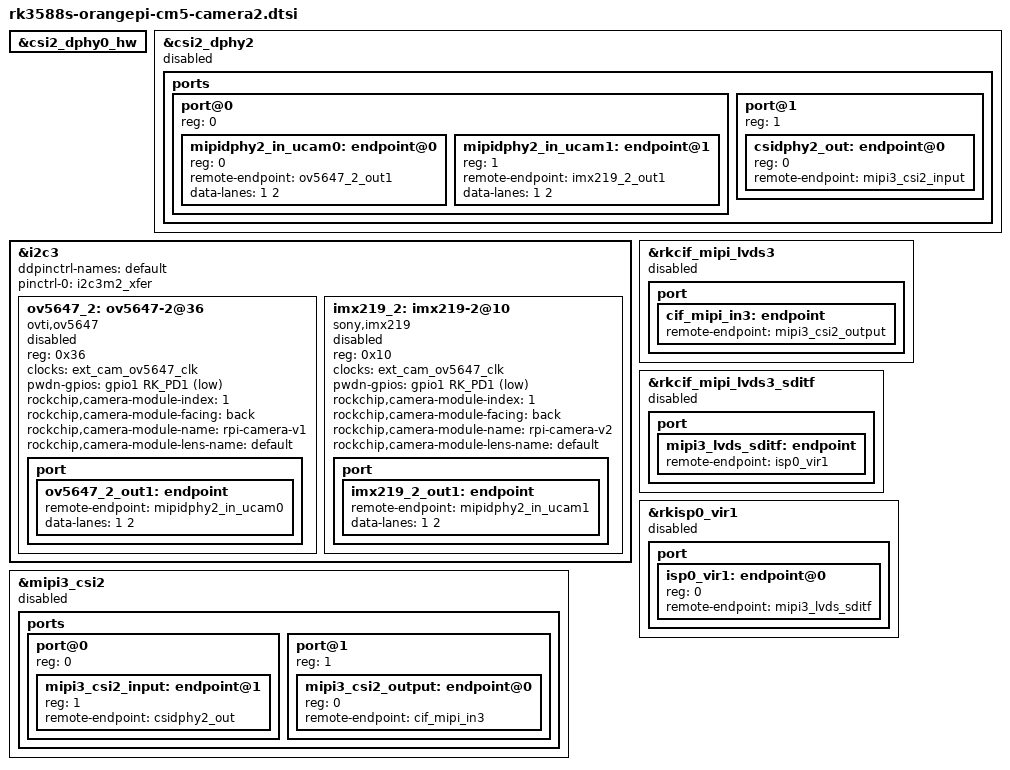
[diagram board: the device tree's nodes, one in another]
// SPDX-License-Identifier: (GPL-2.0+ OR MIT)
/*
 * Copyright (c) 2021 Rockchip Electronics Co., Ltd.
 *
 */

&csi2_dphy0_hw {
	status = "okay";
};

&csi2_dphy2 {
	status = "disabled";
	ports {
		#address-cells = <1>;
		#size-cells = <0>;
		port@0 {
			reg = <0>;
			#address-cells = <1>;
			#size-cells = <0>;

			mipidphy2_in_ucam0: endpoint@0 {
				reg = <0>;
				remote-endpoint = <&ov5647_2_out1>;
				data-lanes = <1 2>;
			};

			mipidphy2_in_ucam1: endpoint@1 {
				reg = <1>;
				remote-endpoint = <&imx219_2_out1>;
				data-lanes = <1 2>;
			};
		};
		port@1 {
		        reg = <1>;
		        #address-cells = <1>;
		        #size-cells = <0>;
		        csidphy2_out: endpoint@0 {
		                reg = <0>;
		                remote-endpoint = <&mipi3_csi2_input>;
		        };
		};
	};
};

&i2c3 {
	status = "okay";
	ddpinctrl-names = "default";
	pinctrl-0 = <&i2c3m2_xfer>;

	ov5647_2: ov5647-2@36 {
		status = "disabled";
		compatible = "ovti,ov5647";
		reg = <0x36>;
		clocks = <&ext_cam_ov5647_clk>;
		clock-names = "ext_cam_ov5647_clk";
		pwdn-gpios = <&gpio1 RK_PD1 GPIO_ACTIVE_LOW>;
		rockchip,camera-module-index = <1>;
		rockchip,camera-module-facing = "back";
		rockchip,camera-module-name = "rpi-camera-v1";
		rockchip,camera-module-lens-name = "default";
		port {
			ov5647_2_out1: endpoint {
				remote-endpoint = <&mipidphy2_in_ucam0>;
				data-lanes = <1 2>;
			};
		};
	};

	imx219_2: imx219-2@10 {
		status = "disabled";
		compatible = "sony,imx219";
		reg = <0x10>;
		clocks = <&ext_cam_ov5647_clk>;
		clock-names = "ext_cam_ov5647_clk";
		pwdn-gpios = <&gpio1 RK_PD1 GPIO_ACTIVE_LOW>;
		rockchip,camera-module-index = <1>;
		rockchip,camera-module-facing = "back";
		rockchip,camera-module-name = "rpi-camera-v2";
		rockchip,camera-module-lens-name = "default";
		port {
			imx219_2_out1: endpoint {
				remote-endpoint = <&mipidphy2_in_ucam1>;
				data-lanes = <1 2>;
			};
		};
	};
};

&mipi3_csi2 {
	status = "disabled";
	ports {
		#address-cells = <1>;
		#size-cells = <0>;
		port@0 {
			reg = <0>;
			#address-cells = <1>;
			#size-cells = <0>;
			mipi3_csi2_input: endpoint@1 {
				reg = <1>;
				remote-endpoint = <&csidphy2_out>;
			};
		};
		port@1 {
			reg = <1>;
			#address-cells = <1>;
			#size-cells = <0>;
			mipi3_csi2_output: endpoint@0 {
				reg = <0>;
				remote-endpoint = <&cif_mipi_in3>;
			};
		};
	};
};

&rkcif_mipi_lvds3 {
	status = "disabled";
	port {
		cif_mipi_in3: endpoint {
			remote-endpoint = <&mipi3_csi2_output>;
		};
	};
};

&rkcif_mipi_lvds3_sditf {
	status = "disabled";
	port {
		mipi3_lvds_sditf: endpoint {
			remote-endpoint = <&isp0_vir1>;
		};
	};
};

&rkisp0_vir1 {
	status = "disabled";
	port {
		#address-cells = <1>;
		#size-cells = <0>;
		isp0_vir1: endpoint@0 {
			reg = <0>;
			remote-endpoint = <&mipi3_lvds_sditf>;
		};
	};
};
